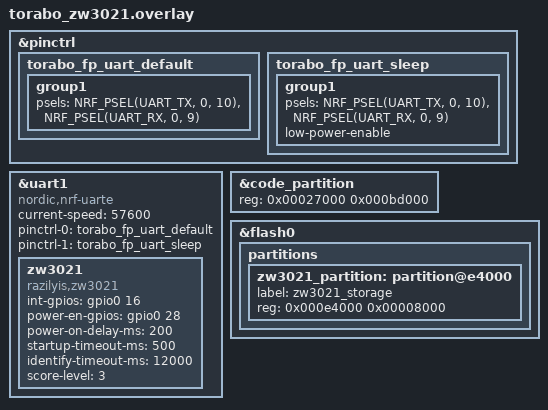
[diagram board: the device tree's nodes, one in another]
// Add-on for torabo_chan; requires the wiring documented in docs/ZW3021.md.
// P0.16 is a direct module connection, NOT a D0..D10 header pin.
#include <zephyr/dt-bindings/gpio/gpio.h>
#include <zephyr/dt-bindings/pinctrl/nrf-pinctrl.h>

&pinctrl {
    torabo_fp_uart_default: torabo_fp_uart_default {
        group1 {
            psels = <NRF_PSEL(UART_TX, 0, 10)>,
                    <NRF_PSEL(UART_RX, 0, 9)>;
        };
    };
    torabo_fp_uart_sleep: torabo_fp_uart_sleep {
        group1 {
            psels = <NRF_PSEL(UART_TX, 0, 10)>,
                    <NRF_PSEL(UART_RX, 0, 9)>;
            low-power-enable;
        };
    };
};

&uart1 {
    status = "okay";
    compatible = "nordic,nrf-uarte";
    current-speed = <57600>;
    pinctrl-0 = <&torabo_fp_uart_default>;
    pinctrl-1 = <&torabo_fp_uart_sleep>;
    pinctrl-names = "default", "sleep";

    zw3021: zw3021 {
        compatible = "razilyis,zw3021";
        status = "okay";
        int-gpios = <&gpio0 16 (GPIO_PULL_DOWN | GPIO_ACTIVE_HIGH)>;
        power-en-gpios = <&gpio0 28 GPIO_ACTIVE_HIGH>; // D2 -> load switch EN
        power-on-delay-ms = <200>;
        startup-timeout-ms = <500>;
        identify-timeout-ms = <12000>;
        score-level = <3>;
    };
};

// Keep the existing ZMK settings and bootloader partitions at their old addresses.
&code_partition { reg = <0x00027000 0x000bd000>; };
&flash0 {
    partitions {
        zw3021_partition: partition@e4000 {
            label = "zw3021_storage";
            reg = <0x000e4000 0x00008000>;
        };
    };
};
